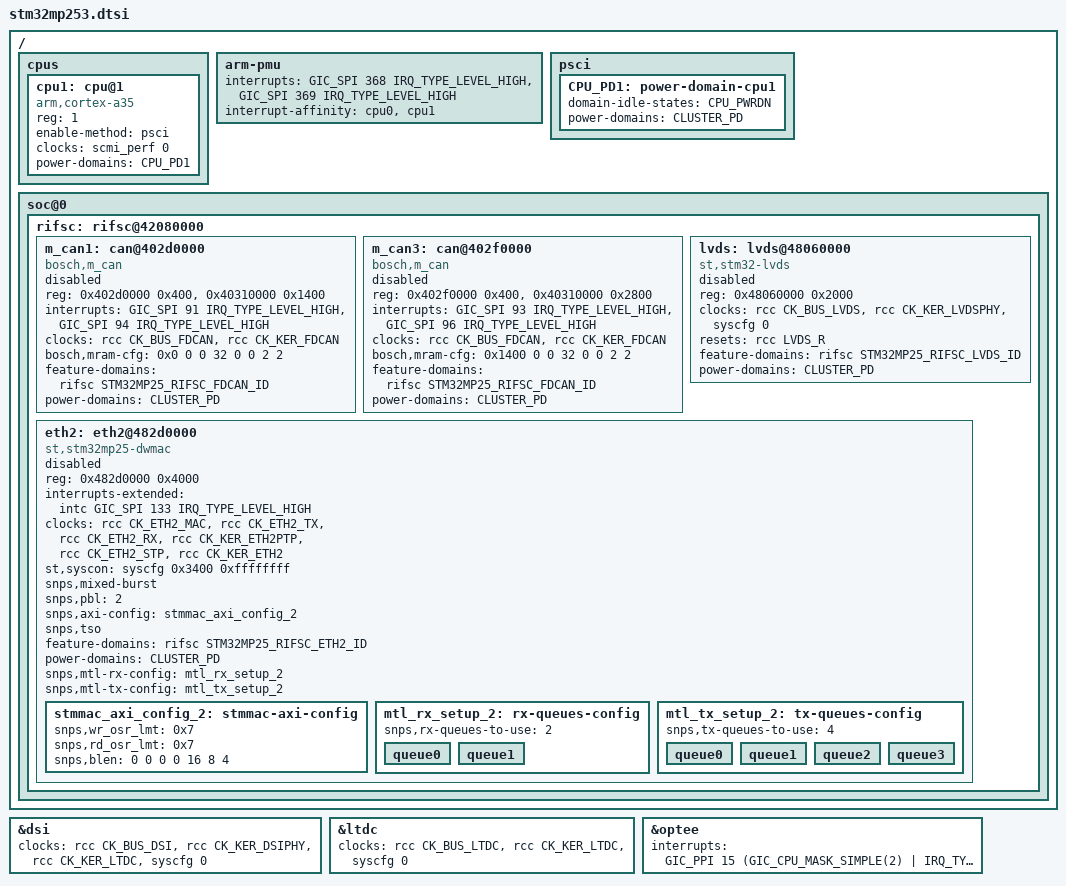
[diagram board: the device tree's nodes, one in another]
// SPDX-License-Identifier: (GPL-2.0-or-later OR BSD-3-Clause)
/*
 * Copyright (C) STMicroelectronics 2023 - All Rights Reserved
 * Author: Alexandre Torgue <alexandre.torgue@foss.st.com> for STMicroelectronics.
 */
#include "stm32mp251.dtsi"

/ {
	cpus {
		cpu1: cpu@1 {
			compatible = "arm,cortex-a35";
			device_type = "cpu";
			reg = <1>;
			enable-method = "psci";
			clocks = <&scmi_perf 0>;
			clock-names = "cpu";
			power-domains = <&CPU_PD1>;
			power-domain-names = "psci";
		};
	};

	arm-pmu {
		interrupts = <GIC_SPI 368 IRQ_TYPE_LEVEL_HIGH>,
			     <GIC_SPI 369 IRQ_TYPE_LEVEL_HIGH>;
		interrupt-affinity = <&cpu0>, <&cpu1>;
	};

	psci {
		CPU_PD1: power-domain-cpu1 {
			#power-domain-cells = <0>;
			domain-idle-states =  <&CPU_PWRDN>;
			power-domains = <&CLUSTER_PD>;
		};
	};

	soc@0 {
		rifsc: rifsc@42080000 {
			m_can1: can@402d0000 {
				compatible = "bosch,m_can";
				reg = <0x402d0000 0x400>, <0x40310000 0x1400>;
				reg-names = "m_can", "message_ram";
				interrupts = <GIC_SPI 91 IRQ_TYPE_LEVEL_HIGH>,
					     <GIC_SPI 94 IRQ_TYPE_LEVEL_HIGH>;
				interrupt-names = "int0", "int1";
				clocks = <&rcc CK_BUS_FDCAN>, <&rcc CK_KER_FDCAN>;
				clock-names = "hclk", "cclk";
				bosch,mram-cfg = <0x0 0 0 32 0 0 2 2>;
				feature-domains = <&rifsc STM32MP25_RIFSC_FDCAN_ID>;
				power-domains = <&CLUSTER_PD>;
				status = "disabled";
			};

			m_can3: can@402f0000 {
				compatible = "bosch,m_can";
				reg = <0x402f0000 0x400>, <0x40310000 0x2800>;
				reg-names = "m_can", "message_ram";
				interrupts = <GIC_SPI 93 IRQ_TYPE_LEVEL_HIGH>,
					     <GIC_SPI 96 IRQ_TYPE_LEVEL_HIGH>;
				interrupt-names = "int0", "int1";
				clocks = <&rcc CK_BUS_FDCAN>, <&rcc CK_KER_FDCAN>;
				clock-names = "hclk", "cclk";
				bosch,mram-cfg = <0x1400 0 0 32 0 0 2 2>;
				feature-domains = <&rifsc STM32MP25_RIFSC_FDCAN_ID>;
				power-domains = <&CLUSTER_PD>;
				status = "disabled";
			};

			lvds: lvds@48060000 {
				#clock-cells = <0>;
				compatible = "st,stm32-lvds";
				reg = <0x48060000 0x2000>;
				clocks = <&rcc CK_BUS_LVDS>, <&rcc CK_KER_LVDSPHY>,
					 <&syscfg 0>;
				clock-names = "pclk", "ref", "pixclk";
				resets = <&rcc LVDS_R>;
				feature-domains = <&rifsc STM32MP25_RIFSC_LVDS_ID>;
				power-domains = <&CLUSTER_PD>;
				status = "disabled";
			};

			eth2: eth2@482d0000 {
				compatible = "st,stm32mp25-dwmac", "snps,dwmac-5.10a";
				reg = <0x482d0000 0x4000>;
				reg-names = "stmmaceth";
				interrupts-extended = <&intc GIC_SPI 133 IRQ_TYPE_LEVEL_HIGH>;
				interrupt-names = "macirq";
				clock-names = "stmmaceth",
					      "mac-clk-tx",
					      "mac-clk-rx",
					      "ptp_ref",
					      "ethstp",
					      "eth-ck";
				clocks = <&rcc CK_ETH2_MAC>,
					 <&rcc CK_ETH2_TX>,
					 <&rcc CK_ETH2_RX>,
					 <&rcc CK_KER_ETH2PTP>,
					 <&rcc CK_ETH2_STP>,
					 <&rcc CK_KER_ETH2>;
				st,syscon = <&syscfg 0x3400 0xffffffff>;
				snps,mixed-burst;
				snps,pbl = <2>;
				snps,axi-config = <&stmmac_axi_config_2>;
				snps,tso;
				feature-domains = <&rifsc STM32MP25_RIFSC_ETH2_ID>;
				power-domains = <&CLUSTER_PD>;
				status = "disabled";
				snps,mtl-rx-config = <&mtl_rx_setup_2>;
				snps,mtl-tx-config = <&mtl_tx_setup_2>;

				stmmac_axi_config_2: stmmac-axi-config {
					snps,wr_osr_lmt = <0x7>;
					snps,rd_osr_lmt = <0x7>;
					snps,blen = <0 0 0 0 16 8 4>;
				};

				mtl_rx_setup_2: rx-queues-config {
					snps,rx-queues-to-use = <2>;
					queue0 {};
					queue1 {};
				};

				mtl_tx_setup_2: tx-queues-config {
					snps,tx-queues-to-use = <4>;
					queue0 {};
					queue1 {};
					queue2 {};
					queue3 {};
				};
			};
		};
	};
};

&dsi {
	clocks = <&rcc CK_BUS_DSI>, <&rcc CK_KER_DSIPHY>,
		 <&rcc CK_KER_LTDC>, <&syscfg 0>;
	clock-names = "pclk", "ref", "px_clk", "pixclk";
};

&ltdc {
	clocks = <&rcc CK_BUS_LTDC>, <&rcc CK_KER_LTDC>, <&syscfg 0>;
	clock-names = "bus", "ref", "lcd";
};

&optee {
	interrupts = <GIC_PPI 15 (GIC_CPU_MASK_SIMPLE(2) | IRQ_TYPE_LEVEL_LOW)>;
};
